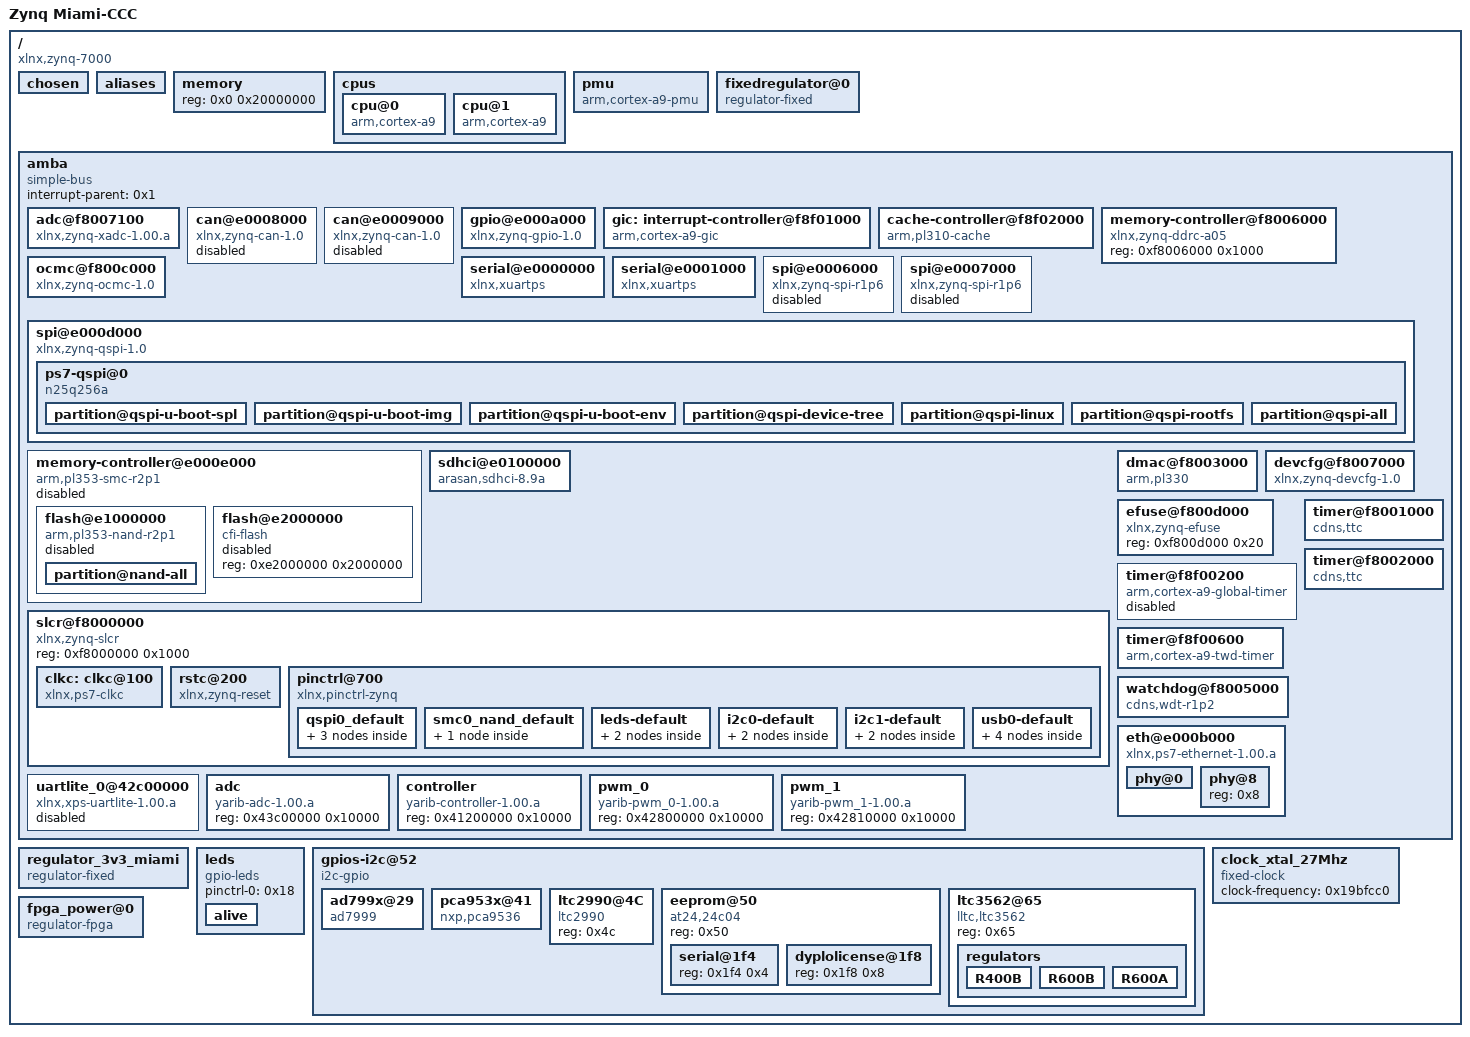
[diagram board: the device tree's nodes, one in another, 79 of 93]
/dts-v1/;

/ {
	#address-cells = <0x1>;
	#size-cells = <0x1>;
	compatible = "xlnx,zynq-7000";
	model = "Zynq Miami-CCC";
	interrupt-parent = <0x1>;

	chosen {

		bootargs = "console=ttyPS0,115200 root=/dev/mtdblock5 ro rootfstype=squashfs rootwait quiet";
		linux,stdout-path = "/amba@0/uart@e0000000";
	};

	aliases {
		serial0 = "/amba/serial@e0000000";
		serial1 = "/amba/serial@e0001000";
		ethernet0 = "/amba/eth@e000b000";
		mmc0 = "/amba/sdhci@e0100000";
		ulrs0 = "/amba/uartlite_0@42c00000";
	};

	memory {
		device_type = "memory";
		reg = <0x0 0x20000000>;
	};

	cpus {
		#address-cells = <0x1>;
		#size-cells = <0x0>;

		cpu@0 {
			compatible = "arm,cortex-a9";
			device_type = "cpu";
			reg = <0x0>;
			clocks = <0x2 0x3>;
			clock-latency = <0x3e8>;
			cpu0-supply = <0x3>;
			operating-points = <0xa2c2b 0xf4240 0x51616 0xf4240>;
		};

		cpu@1 {
			compatible = "arm,cortex-a9";
			device_type = "cpu";
			reg = <0x1>;
			clocks = <0x2 0x3>;
		};
	};

	pmu {
		compatible = "arm,cortex-a9-pmu";
		interrupts = <0x0 0x5 0x4 0x0 0x6 0x4>;
		interrupt-parent = <0x1>;
		reg = <0xf8891000 0x1000 0xf8893000 0x1000>;
	};

	fixedregulator@0 {
		compatible = "regulator-fixed";
		regulator-name = "VCCPINT";
		regulator-min-microvolt = <0xf4240>;
		regulator-max-microvolt = <0xf4240>;
		regulator-boot-on;
		regulator-always-on;
		linux,phandle = <0x3>;
		phandle = <0x3>;
	};

	amba {
		compatible = "simple-bus";
		#address-cells = <0x1>;
		#size-cells = <0x1>;
		interrupt-parent = <0x1>;
		ranges;

		adc@f8007100 {
			compatible = "xlnx,zynq-xadc-1.00.a";
			reg = <0xf8007100 0x20>;
			interrupts = <0x0 0x7 0x4>;
			interrupt-parent = <0x1>;
			clocks = <0x2 0xc>;
		};

		can@e0008000 {
			compatible = "xlnx,zynq-can-1.0";
			status = "disabled";
			clocks = <0x2 0x13 0x2 0x24>;
			clock-names = "can_clk", "pclk";
			reg = <0xe0008000 0x1000>;
			interrupts = <0x0 0x1c 0x4>;
			interrupt-parent = <0x1>;
			tx-fifo-depth = <0x40>;
			rx-fifo-depth = <0x40>;
		};

		can@e0009000 {
			compatible = "xlnx,zynq-can-1.0";
			status = "disabled";
			clocks = <0x2 0x14 0x2 0x25>;
			clock-names = "can_clk", "pclk";
			reg = <0xe0009000 0x1000>;
			interrupts = <0x0 0x33 0x4>;
			interrupt-parent = <0x1>;
			tx-fifo-depth = <0x40>;
			rx-fifo-depth = <0x40>;
		};

		gpio@e000a000 {
			compatible = "xlnx,zynq-gpio-1.0";
			#gpio-cells = <0x2>;
			clocks = <0x2 0x2a>;
			gpio-controller;
			interrupt-controller;
			#interrupt-cells = <0x2>;
			interrupt-parent = <0x1>;
			interrupts = <0x0 0x14 0x4>;
			reg = <0xe000a000 0x1000>;
			linux,phandle = <0xd>;
			phandle = <0xd>;
		};

		gic:interrupt-controller@f8f01000 {
			compatible = "arm,cortex-a9-gic";
			#interrupt-cells = <0x3>;
			interrupt-controller;
			reg = <0xf8f01000 0x1000 0xf8f00100 0x100>;
			linux,phandle = <0x1>;
			phandle = <0x1>;
		};

		cache-controller@f8f02000 {
			compatible = "arm,pl310-cache";
			reg = <0xf8f02000 0x1000>;
			interrupts = <0x0 0x2 0x4>;
			arm,data-latency = <0x3 0x2 0x2>;
			arm,tag-latency = <0x2 0x2 0x2>;
			cache-unified;
			cache-level = <0x2>;
		};

		memory-controller@f8006000 {
			compatible = "xlnx,zynq-ddrc-a05";
			reg = <0xf8006000 0x1000>;
		};

		ocmc@f800c000 {
			compatible = "xlnx,zynq-ocmc-1.0";
			interrupt-parent = <0x1>;
			interrupts = <0x0 0x3 0x4>;
			reg = <0xf800c000 0x1000>;
		};

		serial@e0000000 {
			compatible = "xlnx,xuartps", "cdns,uart-r1p8";
			status = "okay";
			clocks = <0x2 0x17 0x2 0x28>;
			clock-names = "uart_clk", "pclk";
			reg = <0xe0000000 0x1000>;
			interrupts = <0x0 0x1b 0x4>;
		};
		
		serial@e0001000 {
			compatible = "xlnx,xuartps", "cdns,uart-r1p8";
			status = "okay";
			clocks = <0x2 0x18 0x2 0x29>;
			clock-names = "uart_clk", "pclk";
			reg = <0xe0001000 0x1000>;
			interrupts = <0x0 0x32 0x4>;
		};


		spi@e0006000 {
			compatible = "xlnx,zynq-spi-r1p6";
			reg = <0xe0006000 0x1000>;
			status = "disabled";
			interrupt-parent = <0x1>;
			interrupts = <0x0 0x1a 0x4>;
			clocks = <0x2 0x19 0x2 0x22>;
			clock-names = "ref_clk", "pclk";
			#address-cells = <0x1>;
			#size-cells = <0x0>;
		};

		spi@e0007000 {
			compatible = "xlnx,zynq-spi-r1p6";
			reg = <0xe0007000 0x1000>;
			status = "disabled";
			interrupt-parent = <0x1>;
			interrupts = <0x0 0x31 0x4>;
			clocks = <0x2 0x1a 0x2 0x23>;
			clock-names = "ref_clk", "pclk";
			#address-cells = <0x1>;
			#size-cells = <0x0>;
		};

		spi@e000d000 {
			clock-names = "ref_clk", "pclk";
			clocks = <0x2 0xa 0x2 0x2b>;
			compatible = "xlnx,zynq-qspi-1.0";
			status = "okay";
			interrupt-parent = <0x1>;
			interrupts = <0x0 0x13 0x4>;
			reg = <0xe000d000 0x1000>;
			#address-cells = <0x1>;
			#size-cells = <0x0>;
			pinctrl-names = "default";
			pinctrl-0 = <0x4>;
			is-dual = <0x0>;
			num-cs = <0x1>;

			ps7-qspi@0 {
				compatible = "n25q256a";
				spi-max-frequency = <0x66ff300>;
				spi-tx-bus-width = <0x1>;
				spi-rx-bus-width = <0x4>;
				#address-cells = <0x1>;
				#size-cells = <0x1>;
				reg = <0x0>;

				partition@qspi-u-boot-spl {
					label = "qspi-u-boot-spl";
					reg = <0x0 0x20000>;
				};

				partition@qspi-u-boot-img {
					label = "qspi-u-boot-img";
					reg = <0x20000 0x60000>;
				};

				partition@qspi-u-boot-env {
					label = "qspi-u-boot-env";
					reg = <0x80000 0x20000>;
				};

				partition@qspi-device-tree {
					label = "qspi-device-tree";
					reg = <0xa0000 0x20000>;
				};

				partition@qspi-linux {
					label = "qspi-linux";
					reg = <0xc0000 0x440000>;
				};

				partition@qspi-rootfs {
					label = "qspi-rootfs";
					reg = <0x500000 0x1b00000>;
				};

				partition@qspi-all {
					label = "qspi-all";
					reg = <0x0 0x2000000>;
				};
			};
		};

		memory-controller@e000e000 {
			#address-cells = <0x1>;
			#size-cells = <0x1>;
			status = "disabled";
			clock-names = "memclk", "aclk";
			clocks = <0x2 0xb 0x2 0x2c>;
			compatible = "arm,pl353-smc-r2p1";
			interrupt-parent = <0x1>;
			interrupts = <0x0 0x12 0x4>;
			ranges;
			reg = <0xe000e000 0x1000>;

			flash@e1000000 {
				status = "disabled";
				compatible = "arm,pl353-nand-r2p1";
				reg = <0xe1000000 0x1000000>;
				#address-cells = <0x1>;
				#size-cells = <0x1>;
				pinctrl-names = "default";
				pinctrl-0 = <0x5>;
				arm,nand-cycle-t0 = <0x4>;
				arm,nand-cycle-t1 = <0x4>;
				arm,nand-cycle-t2 = <0x1>;
				arm,nand-cycle-t3 = <0x2>;
				arm,nand-cycle-t4 = <0x2>;
				arm,nand-cycle-t5 = <0x2>;
				arm,nand-cycle-t6 = <0x4>;

				partition@nand-all {
					label = "nand-all";
					reg = <0x0 0x10000000>;
				};
			};

			flash@e2000000 {
				status = "disabled";
				compatible = "cfi-flash";
				reg = <0xe2000000 0x2000000>;
				#address-cells = <0x1>;
				#size-cells = <0x1>;
			};
		};

		sdhci@e0100000 {
			compatible = "arasan,sdhci-8.9a";
			status = "okay";
			clock-names = "clk_xin", "clk_ahb";
			clocks = <0x2 0x15 0x2 0x20>;
			interrupt-parent = <0x1>;
			interrupts = <0x0 0x18 0x4>;
			reg = <0xe0100000 0x1000>;
			broken-adma2;
			disable-wp;
		};



		slcr@f8000000 {
			#address-cells = <0x1>;
			#size-cells = <0x1>;
			compatible = "xlnx,zynq-slcr", "syscon", "simple-mfd";
			reg = <0xf8000000 0x1000>;
			ranges;
			linux,phandle = <0x7>;
			phandle = <0x7>;

			clkc: clkc@100 {
				#clock-cells = <0x1>;
				compatible = "xlnx,ps7-clkc";
				fclk-enable = <0xf>;
				clock-output-names = "armpll", "ddrpll", "iopll", "cpu_6or4x", "cpu_3or2x", "cpu_2x", "cpu_1x", "ddr2x", "ddr3x", "dci", "lqspi", "smc", "pcap", "gem0", "gem1", "fclk0", "fclk1", "fclk2", "fclk3", "can0", "can1", "sdio0", "sdio1", "uart0", "uart1", "spi0", "spi1", "dma", "usb0_aper", "usb1_aper", "gem0_aper", "gem1_aper", "sdio0_aper", "sdio1_aper", "spi0_aper", "spi1_aper", "can0_aper", "can1_aper", "i2c0_aper", "i2c1_aper", "uart0_aper", "uart1_aper", "gpio_aper", "lqspi_aper", "smc_aper", "swdt", "dbg_trc", "dbg_apb";
				reg = <0x100 0x100>;
				linux,phandle = <0x2>;
				phandle = <0x2>;
			};

			rstc@200 {
				compatible = "xlnx,zynq-reset";
				reg = <0x200 0x48>;
				#reset-cells = <0x1>;
				syscon = <0x7>;
			};

			pinctrl@700 {
				compatible = "xlnx,pinctrl-zynq";
				reg = <0x700 0x200>;
				syscon = <0x7>;

				qspi0_default {
					linux,phandle = <0x4>;
					phandle = <0x4>;

					mux {
						groups = "qspi0_0_grp";
						function = "qspi0";
					};

					mux-fbclk {
						groups = "qspi_fbclk_grp";
						function = "qspi_fbclk";
					};

					conf {
						groups = "qspi0_0_grp", "qspi_fbclk_grp";
						slew-rate = <0x0>;
						io-standard = <0x1>;
						bias-disable;
					};
				};

				smc0_nand_default {
					linux,phandle = <0x5>;
					phandle = <0x5>;

					mux {
						groups = "smc0_nand_grp";
						function = "smc0_nand";
					};
				};

				leds-default {
					linux,phandle = <0x18>;
					phandle = <0x18>;

					mux {
						groups = "gpio0_25_grp";
						function = "gpio0";
					};

					conf {
						groups = "gpio0_25_grp";
						slew-rate = <0x0>;
						io-standard = <0x1>;
					};
				};

				i2c0-default {
					linux,phandle = <0x19>;
					phandle = <0x19>;

					mux {
						groups = "gpio0_50_grp", "gpio0_51_grp";
						function = "gpio0";
					};

					conf {
						groups = "gpio0_50_grp", "gpio0_51_grp";
						bias-pull-up;
						slew-rate = <0x0>;
						io-standard = <0x1>;
					};
				};

				i2c1-default {
					linux,phandle = <0x1e>;
					phandle = <0x1e>;

					mux {
						groups = "gpio0_52_grp", "gpio0_53_grp";
						function = "gpio0";
					};

					conf {
						groups = "gpio0_52_grp", "gpio0_53_grp";
						bias-pull-up;
						slew-rate = <0x0>;
						io-standard = <0x1>;
					};
				};

				usb0-default {
					linux,phandle = <0xa>;
					phandle = <0xa>;

					mux {
						groups = "usb0_0_grp";
						function = "usb0";
					};

					conf {
						groups = "usb0_0_grp";
						slew-rate = <0x0>;
						io-standard = <0x1>;
					};

					conf-rx {
						pins = "MIO29", "MIO31", "MIO36";
						bias-high-impedance;
					};

					conf-tx {
						pins = "MIO28", "MIO30", "MIO32", "MIO33", "MIO34", "MIO35", "MIO37", "MIO38", "MIO39";
						bias-disable;
					};
				};
			};
		};

		dmac@f8003000 {
			compatible = "arm,pl330", "arm,primecell";
			reg = <0xf8003000 0x1000>;
			interrupt-parent = <0x1>;
			interrupt-names = "abort", "dma0", "dma1", "dma2", "dma3", "dma4", "dma5", "dma6", "dma7";
			interrupts = <0x0 0xd 0x4 0x0 0xe 0x4 0x0 0xf 0x4 0x0 0x10 0x4 0x0 0x11 0x4 0x0 0x28 0x4 0x0 0x29 0x4 0x0 0x2a 0x4 0x0 0x2b 0x4>;
			#dma-cells = <0x1>;
			#dma-channels = <0x8>;
			#dma-requests = <0x4>;
			clocks = <0x2 0x1b>;
			clock-names = "apb_pclk";
			linux,phandle = <0x11>;
			phandle = <0x11>;
		};

		devcfg@f8007000 {
			compatible = "xlnx,zynq-devcfg-1.0";
			interrupt-parent = <0x1>;
			interrupts = <0x0 0x8 0x4>;
			reg = <0xf8007000 0x100>;
			clocks = <0x2 0xc 0x2 0xf 0x2 0x10 0x2 0x11 0x2 0x12>;
			clock-names = "ref_clk", "fclk0", "fclk1", "fclk2", "fclk3";
			syscon = <0x7>;
		};

		efuse@f800d000 {
			compatible = "xlnx,zynq-efuse";
			reg = <0xf800d000 0x20>;
		};

		timer@f8f00200 {
			compatible = "arm,cortex-a9-global-timer";
			reg = <0xf8f00200 0x20>;
			interrupts = <0x1 0xb 0x301>;
			interrupt-parent = <0x1>;
			clocks = <0x2 0x4>;
			status = "disabled";
		};

		timer@f8001000 {
			interrupt-parent = <0x1>;
			interrupts = <0x0 0xa 0x4 0x0 0xb 0x4 0x0 0xc 0x4>;
			compatible = "cdns,ttc";
			clocks = <0x2 0x6>;
			reg = <0xf8001000 0x1000>;
		};

		timer@f8002000 {
			interrupt-parent = <0x1>;
			interrupts = <0x0 0x25 0x4 0x0 0x26 0x4 0x0 0x27 0x4>;
			compatible = "cdns,ttc";
			clocks = <0x2 0x6>;
			reg = <0xf8002000 0x1000>;
		};

		timer@f8f00600 {
			interrupt-parent = <0x1>;
			interrupts = <0x1 0xd 0x301>;
			compatible = "arm,cortex-a9-twd-timer";
			reg = <0xf8f00600 0x20>;
			clocks = <0x2 0x4>;
		};

		


		watchdog@f8005000 {
			clocks = <0x2 0x2d>;
			compatible = "cdns,wdt-r1p2";
			interrupt-parent = <0x1>;
			interrupts = <0x0 0x9 0x1>;
			reg = <0xf8005000 0x1000>;
			timeout-sec = <0xa>;
		};

		eth@e000b000 {
			status = "okay";
			compatible = "xlnx,ps7-ethernet-1.00.a";
			reg = <0xe000b000 0x1000>;
			interrupts = <0x0 0x16 0x4>;
			interrupt-parent = <0x1>;
			#address-cells = <0x1>;
			#size-cells = <0x0>;
			clock-names = "ref_clk", "aper_clk";
			clocks = <0x2 0xd 0x2 0x1e>;
			xlnx,enet-clk-freq-hz = <0x17d7840>;
			xlnx,enet-reset = "MIO 11";
			xlnx,enet-slcr-1000mbps-div0 = <0x8>;
			xlnx,enet-slcr-1000mbps-div1 = <0x1>;
			xlnx,enet-slcr-100mbps-div0 = <0x8>;
			xlnx,enet-slcr-100mbps-div1 = <0x5>;
			xlnx,enet-slcr-10mbps-div0 = <0x8>;
			xlnx,enet-slcr-10mbps-div1 = <0x32>;
			xlnx,eth-mode = <0x1>;
			xlnx,has-mdio = <0x1>;	
			xlnx,ptp-enet-clock = <0x69f6bcb>;
			phy-mode = "gmii";
			phy-handle = <0xb>;
			gmii2rgmii-phy-handle = <0xc>;

			phy@0 {
					reg = <0x0>;
					interrupt-parent = <0x0>;
					interrupts = <0x41 0x8>;
					rxc-skew-ps = <0x438>;
					txc-skew-ps = <0x348>;
					linux,phandle = <0xb>;
					phandle = <0xb>;
				  };

			phy@8 {
					reg = <0x8>;
					linux,phandle = <0xc>;
				  };

		};

		uartlite_0@42c00000 {
			status = "disabled";
            		compatible = "xlnx,xps-uartlite-1.00.a", "xlnx,opb-uartlite-1.00.b", "xlnx,axi-uartlite-1.02.a";
            		reg = <0x42c00000 0x10000>;
            		interrupt-parent = <&gic>;
            		interrupts = <0 59 4>;
            		clock = <100000000>;
       		};


		adc {
			compatible = "yarib-adc-1.00.a";
			reg = <0x43c00000 0x10000>;
		};

		controller {
			compatible = "yarib-controller-1.00.a";
			reg = <0x41200000 0x10000>;
		};

		pwm_0 {
			compatible = "yarib-pwm_0-1.00.a";
			reg = <0x42800000 0x10000>;
		};

		pwm_1 {
			compatible = "yarib-pwm_1-1.00.a";
			reg = <0x42810000 0x10000>;
		};

		

	};

	regulator_3v3_miami {
		compatible = "regulator-fixed";
		regulator-name = "3v3-miami";
		regulator-min-microvolt = <0x325aa0>;
		regulator-max-microvolt = <0x325aa0>;
		linux,phandle = <0x1f>;
		phandle = <0x1f>;
	};

	leds {
		compatible = "gpio-leds";
		pinctrl-names = "default";
		pinctrl-0 = <0x18>;

		alive {
			label = "alive:green";
			gpios = <0xd 0x19 0x0>;
			linux,default-trigger = "heartbeat";
		};
	};

	
	

	gpios-i2c@52 {
		bus-id = <0x1>;
		compatible = "i2c-gpio";
		gpios = <0xd 0x35 0x0 0xd 0x34 0x0>;
		i2c-gpio,delay-us = <0x3>;
		#address-cells = <0x1>;
		#size-cells = <0x0>;
		pinctrl-names = "default";
		pinctrl-0 = <0x1e>;

		ad799x@29 {
			compatible = "ad7999";
			reg = <0x29>;
			vcc-supply = <0x1f>;
			vref-supply = <0x1f>;
		};

		pca953x@41 {
			compatible = "nxp,pca9536";
			reg = <0x41>;
			gpio-controller;
			#gpio-cells = <0x2>;
			linux,phandle = <0x9>;
			phandle = <0x9>;
		};

		ltc2990@4C {
			compatible = "ltc2990";
			reg = <0x4c>;
		};

		eeprom@50 {
			compatible = "at24,24c04";
			reg = <0x50>;
			#address-cells = <0x1>;
			#size-cells = <0x1>;

			serial@1f4 {
				reg = <0x1f4 0x4>;
			};

			dyplolicense@1f8 {
				reg = <0x1f8 0x8>;
			};
		};

		ltc3562@65 {
			compatible = "lltc,ltc3562";
			reg = <0x65>;

			regulators {

				R400B {
					regulator-min-microvolt = <0x1b7740>;
					regulator-max-microvolt = <0x1b7740>;
					regulator-boot-on;
					regulator-always-on;
					lltc,operating-mode = <0x1>;
				};

				R600B {
					regulator-min-microvolt = <0x325aa0>;
					regulator-max-microvolt = <0x325aa0>;
					regulator-boot-on;
					regulator-always-on;
				};

				R600A {
					regulator-min-microvolt = <0x1afa40>;
					regulator-max-microvolt = <0x1afa40>;
					lltc,fb-voltage-divider = <0x13c 0x64>;
					regulator-boot-on;
					regulator-always-on;
				};
			};
		};
	};

	

	clock_xtal_27Mhz {
		compatible = "fixed-clock";
		#clock-cells = <0x0>;
		clock-frequency = <0x19bfcc0>;
		linux,phandle = <0x1a>;
		phandle = <0x1a>;
	};



	fpga_power@0 {
		compatible = "regulator-fpga";
		regulator-name = "FPGA power";
		regulator-always-on;
		linux,phandle = <0x20>;
		phandle = <0x20>;
	};


};
